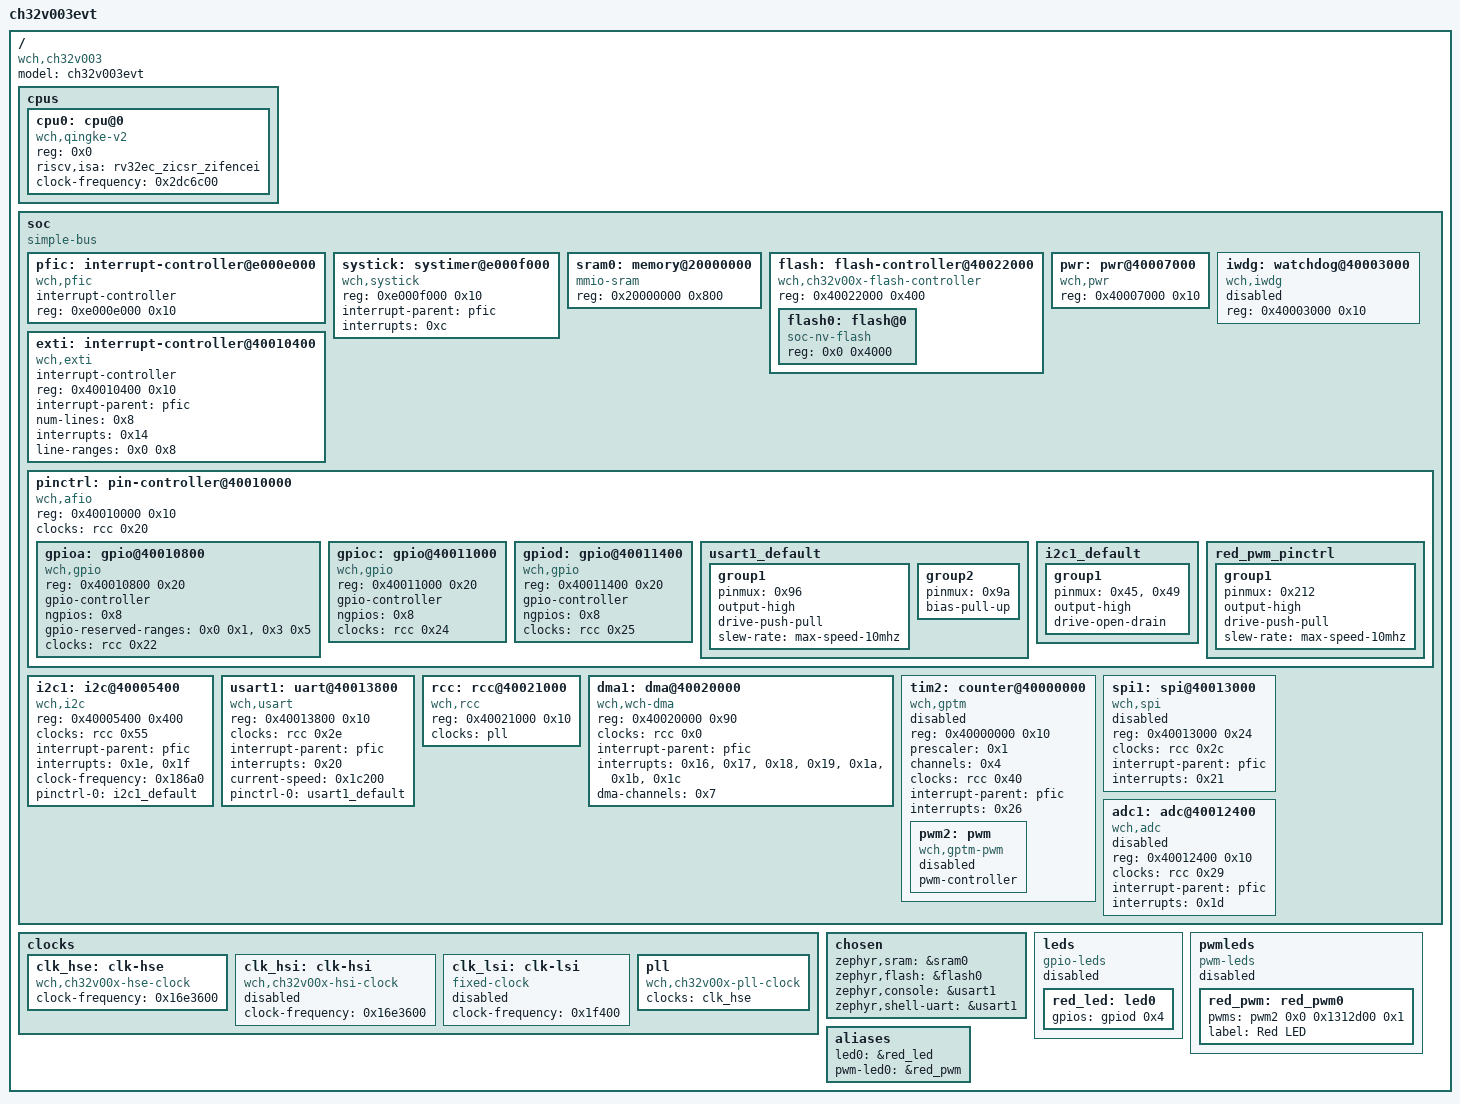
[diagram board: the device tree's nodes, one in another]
/dts-v1/;

/* node '/' defined in zephyr/dts/riscv/wch/qingke-v2a.dtsi:7 */
/ {
	#address-cells = < 0x1 >;    /* in zephyr/dts/riscv/wch/qingke-v2a.dtsi:8 */
	#size-cells = < 0x1 >;       /* in zephyr/dts/riscv/wch/qingke-v2a.dtsi:9 */
	model = "ch32v003evt";       /* in zephyr/boards/wch/ch32v003evt/ch32v003evt.dts:16 */
	compatible = "wch,ch32v003"; /* in zephyr/boards/wch/ch32v003evt/ch32v003evt.dts:17 */

	/* node '/cpus' defined in zephyr/dts/riscv/wch/qingke-v2a.dtsi:11 */
	cpus {
		#address-cells = < 0x1 >; /* in zephyr/dts/riscv/wch/qingke-v2a.dtsi:12 */
		#size-cells = < 0x0 >;    /* in zephyr/dts/riscv/wch/qingke-v2a.dtsi:13 */

		/* node '/cpus/cpu@0' defined in zephyr/dts/riscv/wch/qingke-v2a.dtsi:15 */
		cpu0: cpu@0 {
			device_type = "cpu";                 /* in zephyr/dts/riscv/wch/qingke-v2a.dtsi:16 */
			compatible = "wch,qingke-v2";        /* in zephyr/dts/riscv/wch/qingke-v2a.dtsi:17 */
			reg = < 0x0 >;                       /* in zephyr/dts/riscv/wch/qingke-v2a.dtsi:18 */
			riscv,isa = "rv32ec_zicsr_zifencei"; /* in zephyr/dts/riscv/wch/qingke-v2a.dtsi:19 */
			clock-frequency = < 0x2dc6c00 >;     /* in zephyr/dts/riscv/wch/ch32v0/ch32v003.dtsi:203 */
		};
	};

	/* node '/soc' defined in zephyr/dts/riscv/wch/qingke-v2a.dtsi:23 */
	soc {
		#address-cells = < 0x1 >;  /* in zephyr/dts/riscv/wch/qingke-v2a.dtsi:24 */
		#size-cells = < 0x1 >;     /* in zephyr/dts/riscv/wch/qingke-v2a.dtsi:25 */
		compatible = "simple-bus"; /* in zephyr/dts/riscv/wch/qingke-v2a.dtsi:26 */
		ranges;                    /* in zephyr/dts/riscv/wch/qingke-v2a.dtsi:27 */

		/* node '/soc/interrupt-controller@e000e000' defined in zephyr/dts/riscv/wch/qingke-v2a.dtsi:29 */
		pfic: interrupt-controller@e000e000 {
			compatible = "wch,pfic";    /* in zephyr/dts/riscv/wch/qingke-v2a.dtsi:30 */
			#address-cells = < 0x0 >;   /* in zephyr/dts/riscv/wch/qingke-v2a.dtsi:31 */
			#interrupt-cells = < 0x1 >; /* in zephyr/dts/riscv/wch/qingke-v2a.dtsi:32 */
			interrupt-controller;       /* in zephyr/dts/riscv/wch/qingke-v2a.dtsi:33 */
			reg = < 0xe000e000 0x10 >;  /* in zephyr/dts/riscv/wch/qingke-v2a.dtsi:34 */
			status = "okay";            /* in zephyr/dts/riscv/wch/qingke-v2a.dtsi:35 */
			phandle = < 0x1 >;          /* in zephyr/dts/riscv/wch/qingke-v2a.dtsi:42 */
		};

		/* node '/soc/systimer@e000f000' defined in zephyr/dts/riscv/wch/qingke-v2a.dtsi:38 */
		systick: systimer@e000f000 {
			compatible = "wch,systick";   /* in zephyr/dts/riscv/wch/qingke-v2a.dtsi:39 */
			reg = < 0xe000f000 0x10 >;    /* in zephyr/dts/riscv/wch/qingke-v2a.dtsi:40 */
			status = "okay";              /* in zephyr/dts/riscv/wch/qingke-v2a.dtsi:41 */
			interrupt-parent = < &pfic >; /* in zephyr/dts/riscv/wch/qingke-v2a.dtsi:42 */
			interrupts = < 0xc >;         /* in zephyr/dts/riscv/wch/qingke-v2a.dtsi:43 */
		};

		/* node '/soc/memory@20000000' defined in zephyr/dts/riscv/wch/ch32v0/ch32v003.dtsi:46 */
		sram0: memory@20000000 {
			compatible = "mmio-sram";   /* in zephyr/dts/riscv/wch/ch32v0/ch32v003.dtsi:47 */
			reg = < 0x20000000 0x800 >; /* in zephyr/dts/riscv/wch/ch32v0/ch32v003.dtsi:48 */
		};

		/* node '/soc/flash-controller@40022000' defined in zephyr/dts/riscv/wch/ch32v0/ch32v003.dtsi:51 */
		flash: flash-controller@40022000 {
			compatible = "wch,ch32v00x-flash-controller"; /* in zephyr/dts/riscv/wch/ch32v0/ch32v003.dtsi:52 */
			reg = < 0x40022000 0x400 >;                   /* in zephyr/dts/riscv/wch/ch32v0/ch32v003.dtsi:53 */
			#address-cells = < 0x1 >;                     /* in zephyr/dts/riscv/wch/ch32v0/ch32v003.dtsi:55 */
			#size-cells = < 0x1 >;                        /* in zephyr/dts/riscv/wch/ch32v0/ch32v003.dtsi:56 */

			/* node '/soc/flash-controller@40022000/flash@0' defined in zephyr/dts/riscv/wch/ch32v0/ch32v003.dtsi:58 */
			flash0: flash@0 {
				compatible = "soc-nv-flash"; /* in zephyr/dts/riscv/wch/ch32v0/ch32v003.dtsi:59 */
				reg = < 0x0 0x4000 >;        /* in zephyr/dts/riscv/wch/ch32v0/ch32v003.dtsi:60 */
			};
		};

		/* node '/soc/pwr@40007000' defined in zephyr/dts/riscv/wch/ch32v0/ch32v003.dtsi:64 */
		pwr: pwr@40007000 {
			compatible = "wch,pwr";    /* in zephyr/dts/riscv/wch/ch32v0/ch32v003.dtsi:65 */
			reg = < 0x40007000 0x10 >; /* in zephyr/dts/riscv/wch/ch32v0/ch32v003.dtsi:66 */
		};

		/* node '/soc/watchdog@40003000' defined in zephyr/dts/riscv/wch/ch32v0/ch32v003.dtsi:69 */
		iwdg: watchdog@40003000 {
			compatible = "wch,iwdg";   /* in zephyr/dts/riscv/wch/ch32v0/ch32v003.dtsi:70 */
			reg = < 0x40003000 0x10 >; /* in zephyr/dts/riscv/wch/ch32v0/ch32v003.dtsi:71 */
			status = "disabled";       /* in zephyr/dts/riscv/wch/ch32v0/ch32v003.dtsi:72 */
		};

		/* node '/soc/interrupt-controller@40010400' defined in zephyr/dts/riscv/wch/ch32v0/ch32v003.dtsi:75 */
		exti: interrupt-controller@40010400 {
			compatible = "wch,exti";      /* in zephyr/dts/riscv/wch/ch32v0/ch32v003.dtsi:76 */
			interrupt-controller;         /* in zephyr/dts/riscv/wch/ch32v0/ch32v003.dtsi:77 */
			#interrupt-cells = < 0x1 >;   /* in zephyr/dts/riscv/wch/ch32v0/ch32v003.dtsi:78 */
			reg = < 0x40010400 0x10 >;    /* in zephyr/dts/riscv/wch/ch32v0/ch32v003.dtsi:79 */
			interrupt-parent = < &pfic >; /* in zephyr/dts/riscv/wch/ch32v0/ch32v003.dtsi:80 */
			num-lines = < 0x8 >;          /* in zephyr/dts/riscv/wch/ch32v0/ch32v003.dtsi:81 */
			interrupts = < 0x14 >;        /* in zephyr/dts/riscv/wch/ch32v0/ch32v003.dtsi:82 */
			line-ranges = < 0x0 0x8 >;    /* in zephyr/dts/riscv/wch/ch32v0/ch32v003.dtsi:83 */
			interrupt-names = "line0-7";  /* in zephyr/dts/riscv/wch/ch32v0/ch32v003.dtsi:84 */
			status = "okay";              /* in zephyr/boards/wch/ch32v003evt/ch32v003evt.dts:72 */
		};

		/* node '/soc/pin-controller@40010000' defined in zephyr/dts/riscv/wch/ch32v0/ch32v003.dtsi:88 */
		pinctrl: pin-controller@40010000 {
			compatible = "wch,afio";   /* in zephyr/dts/riscv/wch/ch32v0/ch32v003.dtsi:89 */
			reg = < 0x40010000 0x10 >; /* in zephyr/dts/riscv/wch/ch32v0/ch32v003.dtsi:90 */
			#address-cells = < 0x1 >;  /* in zephyr/dts/riscv/wch/ch32v0/ch32v003.dtsi:91 */
			#size-cells = < 0x1 >;     /* in zephyr/dts/riscv/wch/ch32v0/ch32v003.dtsi:92 */
			clocks = < &rcc 0x20 >;    /* in zephyr/dts/riscv/wch/ch32v0/ch32v003.dtsi:93 */
			status = "okay";           /* in zephyr/dts/riscv/wch/ch32v0/ch32v003.dtsi:94 */

			/* node '/soc/pin-controller@40010000/gpio@40010800' defined in zephyr/dts/riscv/wch/ch32v0/ch32v003.dtsi:96 */
			gpioa: gpio@40010800 {
				compatible = "wch,gpio";            /* in zephyr/dts/riscv/wch/ch32v0/ch32v003.dtsi:97 */
				reg = < 0x40010800 0x20 >;          /* in zephyr/dts/riscv/wch/ch32v0/ch32v003.dtsi:98 */
				gpio-controller;                    /* in zephyr/dts/riscv/wch/ch32v0/ch32v003.dtsi:99 */
				#gpio-cells = < 0x2 >;              /* in zephyr/dts/riscv/wch/ch32v0/ch32v003.dtsi:100 */
				ngpios = < 0x8 >;                   /* in zephyr/dts/riscv/wch/ch32v0/ch32v003.dtsi:101 */
				gpio-reserved-ranges = < 0x0 0x1 >,
				                       < 0x3 0x5 >; /* in zephyr/dts/riscv/wch/ch32v0/ch32v003.dtsi:102 */
				clocks = < &rcc 0x22 >;             /* in zephyr/dts/riscv/wch/ch32v0/ch32v003.dtsi:103 */
			};

			/* node '/soc/pin-controller@40010000/gpio@40011000' defined in zephyr/dts/riscv/wch/ch32v0/ch32v003.dtsi:106 */
			gpioc: gpio@40011000 {
				compatible = "wch,gpio";   /* in zephyr/dts/riscv/wch/ch32v0/ch32v003.dtsi:107 */
				reg = < 0x40011000 0x20 >; /* in zephyr/dts/riscv/wch/ch32v0/ch32v003.dtsi:108 */
				gpio-controller;           /* in zephyr/dts/riscv/wch/ch32v0/ch32v003.dtsi:109 */
				#gpio-cells = < 0x2 >;     /* in zephyr/dts/riscv/wch/ch32v0/ch32v003.dtsi:110 */
				ngpios = < 0x8 >;          /* in zephyr/dts/riscv/wch/ch32v0/ch32v003.dtsi:111 */
				clocks = < &rcc 0x24 >;    /* in zephyr/dts/riscv/wch/ch32v0/ch32v003.dtsi:112 */
				status = "okay";           /* in zephyr/boards/wch/ch32v003evt/ch32v003evt.dts:76 */
			};

			/* node '/soc/pin-controller@40010000/gpio@40011400' defined in zephyr/dts/riscv/wch/ch32v0/ch32v003.dtsi:115 */
			gpiod: gpio@40011400 {
				compatible = "wch,gpio";   /* in zephyr/dts/riscv/wch/ch32v0/ch32v003.dtsi:116 */
				reg = < 0x40011400 0x20 >; /* in zephyr/dts/riscv/wch/ch32v0/ch32v003.dtsi:117 */
				gpio-controller;           /* in zephyr/dts/riscv/wch/ch32v0/ch32v003.dtsi:118 */
				#gpio-cells = < 0x2 >;     /* in zephyr/dts/riscv/wch/ch32v0/ch32v003.dtsi:119 */
				ngpios = < 0x8 >;          /* in zephyr/dts/riscv/wch/ch32v0/ch32v003.dtsi:120 */
				clocks = < &rcc 0x25 >;    /* in zephyr/dts/riscv/wch/ch32v0/ch32v003.dtsi:121 */
				status = "okay";           /* in zephyr/boards/wch/ch32v003evt/ch32v003evt.dts:80 */
				phandle = < 0x7 >;         /* in zephyr/boards/wch/ch32v003evt/ch32v003evt.dts:37 */
			};

			/* node '/soc/pin-controller@40010000/usart1_default' defined in zephyr/boards/wch/ch32v003evt/ch32v003evt-pinctrl.dtsi:9 */
			usart1_default: usart1_default {
				phandle = < 0x4 >; /* in zephyr/boards/wch/ch32v003evt/ch32v003evt.dts:93 */

				/* node '/soc/pin-controller@40010000/usart1_default/group1' defined in zephyr/boards/wch/ch32v003evt/ch32v003evt-pinctrl.dtsi:10 */
				group1 {
					pinmux = < 0x96 >;             /* in zephyr/boards/wch/ch32v003evt/ch32v003evt-pinctrl.dtsi:11 */
					output-high;                   /* in zephyr/boards/wch/ch32v003evt/ch32v003evt-pinctrl.dtsi:12 */
					drive-push-pull;               /* in zephyr/boards/wch/ch32v003evt/ch32v003evt-pinctrl.dtsi:13 */
					slew-rate = "max-speed-10mhz"; /* in zephyr/boards/wch/ch32v003evt/ch32v003evt-pinctrl.dtsi:14 */
				};

				/* node '/soc/pin-controller@40010000/usart1_default/group2' defined in zephyr/boards/wch/ch32v003evt/ch32v003evt-pinctrl.dtsi:17 */
				group2 {
					pinmux = < 0x9a >; /* in zephyr/boards/wch/ch32v003evt/ch32v003evt-pinctrl.dtsi:18 */
					bias-pull-up;      /* in zephyr/boards/wch/ch32v003evt/ch32v003evt-pinctrl.dtsi:19 */
				};
			};

			/* node '/soc/pin-controller@40010000/i2c1_default' defined in zephyr/boards/wch/ch32v003evt/ch32v003evt-pinctrl.dtsi:23 */
			i2c1_default: i2c1_default {
				phandle = < 0x3 >; /* in zephyr/boards/wch/ch32v003evt/ch32v003evt.dts:86 */

				/* node '/soc/pin-controller@40010000/i2c1_default/group1' defined in zephyr/boards/wch/ch32v003evt/ch32v003evt-pinctrl.dtsi:24 */
				group1 {
					pinmux = < 0x45 >,
					         < 0x49 >; /* in zephyr/boards/wch/ch32v003evt/ch32v003evt-pinctrl.dtsi:25 */
					output-high;       /* in zephyr/boards/wch/ch32v003evt/ch32v003evt-pinctrl.dtsi:26 */
					drive-open-drain;  /* in zephyr/boards/wch/ch32v003evt/ch32v003evt-pinctrl.dtsi:27 */
				};
			};

			/* node '/soc/pin-controller@40010000/red_pwm_pinctrl' defined in zephyr/boards/wch/ch32v003evt/ch32v003evt-pinctrl.dtsi:31 */
			red_pwm_pinctrl: red_pwm_pinctrl {

				/* node '/soc/pin-controller@40010000/red_pwm_pinctrl/group1' defined in zephyr/boards/wch/ch32v003evt/ch32v003evt-pinctrl.dtsi:32 */
				group1 {
					pinmux = < 0x212 >;            /* in zephyr/boards/wch/ch32v003evt/ch32v003evt-pinctrl.dtsi:33 */
					output-high;                   /* in zephyr/boards/wch/ch32v003evt/ch32v003evt-pinctrl.dtsi:34 */
					drive-push-pull;               /* in zephyr/boards/wch/ch32v003evt/ch32v003evt-pinctrl.dtsi:35 */
					slew-rate = "max-speed-10mhz"; /* in zephyr/boards/wch/ch32v003evt/ch32v003evt-pinctrl.dtsi:36 */
				};
			};
		};

		/* node '/soc/i2c@40005400' defined in zephyr/dts/riscv/wch/ch32v0/ch32v003.dtsi:125 */
		i2c1: i2c@40005400 {
			compatible = "wch,i2c";        /* in zephyr/dts/riscv/wch/ch32v0/ch32v003.dtsi:126 */
			#address-cells = < 0x1 >;      /* in zephyr/dts/riscv/wch/ch32v0/ch32v003.dtsi:127 */
			#size-cells = < 0x0 >;         /* in zephyr/dts/riscv/wch/ch32v0/ch32v003.dtsi:128 */
			reg = < 0x40005400 0x400 >;    /* in zephyr/dts/riscv/wch/ch32v0/ch32v003.dtsi:129 */
			clocks = < &rcc 0x55 >;        /* in zephyr/dts/riscv/wch/ch32v0/ch32v003.dtsi:130 */
			interrupt-parent = < &pfic >;  /* in zephyr/dts/riscv/wch/ch32v0/ch32v003.dtsi:131 */
			interrupts = < 0x1e >,
			             < 0x1f >;         /* in zephyr/dts/riscv/wch/ch32v0/ch32v003.dtsi:132 */
			status = "okay";               /* in zephyr/boards/wch/ch32v003evt/ch32v003evt.dts:84 */
			clock-frequency = < 0x186a0 >; /* in zephyr/boards/wch/ch32v003evt/ch32v003evt.dts:85 */
			pinctrl-0 = < &i2c1_default >; /* in zephyr/boards/wch/ch32v003evt/ch32v003evt.dts:86 */
			pinctrl-names = "default";     /* in zephyr/boards/wch/ch32v003evt/ch32v003evt.dts:87 */
		};

		/* node '/soc/uart@40013800' defined in zephyr/dts/riscv/wch/ch32v0/ch32v003.dtsi:135 */
		usart1: uart@40013800 {
			compatible = "wch,usart";        /* in zephyr/dts/riscv/wch/ch32v0/ch32v003.dtsi:136 */
			reg = < 0x40013800 0x10 >;       /* in zephyr/dts/riscv/wch/ch32v0/ch32v003.dtsi:137 */
			clocks = < &rcc 0x2e >;          /* in zephyr/dts/riscv/wch/ch32v0/ch32v003.dtsi:138 */
			interrupt-parent = < &pfic >;    /* in zephyr/dts/riscv/wch/ch32v0/ch32v003.dtsi:139 */
			interrupts = < 0x20 >;           /* in zephyr/dts/riscv/wch/ch32v0/ch32v003.dtsi:140 */
			status = "okay";                 /* in zephyr/boards/wch/ch32v003evt/ch32v003evt.dts:91 */
			current-speed = < 0x1c200 >;     /* in zephyr/boards/wch/ch32v003evt/ch32v003evt.dts:92 */
			pinctrl-0 = < &usart1_default >; /* in zephyr/boards/wch/ch32v003evt/ch32v003evt.dts:93 */
			pinctrl-names = "default";       /* in zephyr/boards/wch/ch32v003evt/ch32v003evt.dts:94 */
		};

		/* node '/soc/rcc@40021000' defined in zephyr/dts/riscv/wch/ch32v0/ch32v003.dtsi:143 */
		rcc: rcc@40021000 {
			compatible = "wch,rcc";    /* in zephyr/dts/riscv/wch/ch32v0/ch32v003.dtsi:144 */
			reg = < 0x40021000 0x10 >; /* in zephyr/dts/riscv/wch/ch32v0/ch32v003.dtsi:145 */
			#clock-cells = < 0x1 >;    /* in zephyr/dts/riscv/wch/ch32v0/ch32v003.dtsi:146 */
			status = "okay";           /* in zephyr/dts/riscv/wch/ch32v0/ch32v003.dtsi:147 */
			clocks = < &pll >;         /* in zephyr/boards/wch/ch32v003evt/ch32v003evt.dts:68 */
			phandle = < 0x2 >;         /* in zephyr/dts/riscv/wch/ch32v0/ch32v003.dtsi:93 */
		};

		/* node '/soc/dma@40020000' defined in zephyr/dts/riscv/wch/ch32v0/ch32v003.dtsi:150 */
		dma1: dma@40020000 {
			compatible = "wch,wch-dma";   /* in zephyr/dts/riscv/wch/ch32v0/ch32v003.dtsi:151 */
			reg = < 0x40020000 0x90 >;    /* in zephyr/dts/riscv/wch/ch32v0/ch32v003.dtsi:152 */
			clocks = < &rcc 0x0 >;        /* in zephyr/dts/riscv/wch/ch32v0/ch32v003.dtsi:153 */
			#dma-cells = < 0x1 >;         /* in zephyr/dts/riscv/wch/ch32v0/ch32v003.dtsi:154 */
			interrupt-parent = < &pfic >; /* in zephyr/dts/riscv/wch/ch32v0/ch32v003.dtsi:155 */
			interrupts = < 0x16 >,
			             < 0x17 >,
			             < 0x18 >,
			             < 0x19 >,
			             < 0x1a >,
			             < 0x1b >,
			             < 0x1c >;        /* in zephyr/dts/riscv/wch/ch32v0/ch32v003.dtsi:156 */
			dma-channels = < 0x7 >;       /* in zephyr/dts/riscv/wch/ch32v0/ch32v003.dtsi:157 */
		};

		/* node '/soc/counter@40000000' defined in zephyr/dts/riscv/wch/ch32v0/ch32v003.dtsi:160 */
		tim2: counter@40000000 {
			compatible = "wch,gptm";      /* in zephyr/dts/riscv/wch/ch32v0/ch32v003.dtsi:161 */
			reg = < 0x40000000 0x10 >;    /* in zephyr/dts/riscv/wch/ch32v0/ch32v003.dtsi:162 */
			prescaler = < 0x1 >;          /* in zephyr/dts/riscv/wch/ch32v0/ch32v003.dtsi:163 */
			channels = < 0x4 >;           /* in zephyr/dts/riscv/wch/ch32v0/ch32v003.dtsi:164 */
			clocks = < &rcc 0x40 >;       /* in zephyr/dts/riscv/wch/ch32v0/ch32v003.dtsi:165 */
			interrupt-parent = < &pfic >; /* in zephyr/dts/riscv/wch/ch32v0/ch32v003.dtsi:166 */
			interrupts = < 0x26 >;        /* in zephyr/dts/riscv/wch/ch32v0/ch32v003.dtsi:167 */
			interrupt-names = "global";   /* in zephyr/dts/riscv/wch/ch32v0/ch32v003.dtsi:168 */
			status = "disabled";          /* in zephyr/dts/riscv/wch/ch32v0/ch32v003.dtsi:169 */

			/* node '/soc/counter@40000000/pwm' defined in zephyr/dts/riscv/wch/ch32v0/ch32v003.dtsi:171 */
			pwm2: pwm {
				compatible = "wch,gptm-pwm"; /* in zephyr/dts/riscv/wch/ch32v0/ch32v003.dtsi:172 */
				pwm-controller;              /* in zephyr/dts/riscv/wch/ch32v0/ch32v003.dtsi:173 */
				#pwm-cells = < 0x3 >;        /* in zephyr/dts/riscv/wch/ch32v0/ch32v003.dtsi:174 */
				status = "disabled";         /* in zephyr/dts/riscv/wch/ch32v0/ch32v003.dtsi:175 */
				phandle = < 0x8 >;           /* in zephyr/boards/wch/ch32v003evt/ch32v003evt.dts:46 */
			};
		};

		/* node '/soc/spi@40013000' defined in zephyr/dts/riscv/wch/ch32v0/ch32v003.dtsi:179 */
		spi1: spi@40013000 {
			compatible = "wch,spi";       /* in zephyr/dts/riscv/wch/ch32v0/ch32v003.dtsi:180 */
			reg = < 0x40013000 0x24 >;    /* in zephyr/dts/riscv/wch/ch32v0/ch32v003.dtsi:181 */
			clocks = < &rcc 0x2c >;       /* in zephyr/dts/riscv/wch/ch32v0/ch32v003.dtsi:182 */
			interrupt-parent = < &pfic >; /* in zephyr/dts/riscv/wch/ch32v0/ch32v003.dtsi:183 */
			interrupts = < 0x21 >;        /* in zephyr/dts/riscv/wch/ch32v0/ch32v003.dtsi:184 */
			status = "disabled";          /* in zephyr/dts/riscv/wch/ch32v0/ch32v003.dtsi:185 */
			#address-cells = < 0x1 >;     /* in zephyr/dts/riscv/wch/ch32v0/ch32v003.dtsi:186 */
			#size-cells = < 0x0 >;        /* in zephyr/dts/riscv/wch/ch32v0/ch32v003.dtsi:187 */
		};

		/* node '/soc/adc@40012400' defined in zephyr/dts/riscv/wch/ch32v0/ch32v003.dtsi:190 */
		adc1: adc@40012400 {
			compatible = "wch,adc";       /* in zephyr/dts/riscv/wch/ch32v0/ch32v003.dtsi:191 */
			reg = < 0x40012400 0x10 >;    /* in zephyr/dts/riscv/wch/ch32v0/ch32v003.dtsi:192 */
			clocks = < &rcc 0x29 >;       /* in zephyr/dts/riscv/wch/ch32v0/ch32v003.dtsi:193 */
			interrupt-parent = < &pfic >; /* in zephyr/dts/riscv/wch/ch32v0/ch32v003.dtsi:194 */
			interrupts = < 0x1d >;        /* in zephyr/dts/riscv/wch/ch32v0/ch32v003.dtsi:195 */
			#io-channel-cells = < 0x1 >;  /* in zephyr/dts/riscv/wch/ch32v0/ch32v003.dtsi:196 */
			status = "disabled";          /* in zephyr/dts/riscv/wch/ch32v0/ch32v003.dtsi:197 */
		};
	};

	/* node '/clocks' defined in zephyr/dts/riscv/wch/ch32v0/ch32v003.dtsi:17 */
	clocks {

		/* node '/clocks/clk-hse' defined in zephyr/dts/riscv/wch/ch32v0/ch32v003.dtsi:18 */
		clk_hse: clk-hse {
			#clock-cells = < 0x0 >;                /* in zephyr/dts/riscv/wch/ch32v0/ch32v003.dtsi:19 */
			compatible = "wch,ch32v00x-hse-clock"; /* in zephyr/dts/riscv/wch/ch32v0/ch32v003.dtsi:20 */
			clock-frequency = < 0x16e3600 >;       /* in zephyr/boards/wch/ch32v003evt/ch32v003evt.dts:58 */
			status = "okay";                       /* in zephyr/boards/wch/ch32v003evt/ch32v003evt.dts:59 */
			phandle = < 0x6 >;                     /* in zephyr/boards/wch/ch32v003evt/ch32v003evt.dts:63 */
		};

		/* node '/clocks/clk-hsi' defined in zephyr/dts/riscv/wch/ch32v0/ch32v003.dtsi:24 */
		clk_hsi: clk-hsi {
			#clock-cells = < 0x0 >;                /* in zephyr/dts/riscv/wch/ch32v0/ch32v003.dtsi:25 */
			compatible = "wch,ch32v00x-hsi-clock"; /* in zephyr/dts/riscv/wch/ch32v0/ch32v003.dtsi:26 */
			clock-frequency = < 0x16e3600 >;       /* in zephyr/dts/riscv/wch/ch32v0/ch32v003.dtsi:27 */
			status = "disabled";                   /* in zephyr/dts/riscv/wch/ch32v0/ch32v003.dtsi:28 */
		};

		/* node '/clocks/clk-lsi' defined in zephyr/dts/riscv/wch/ch32v0/ch32v003.dtsi:31 */
		clk_lsi: clk-lsi {
			#clock-cells = < 0x0 >;        /* in zephyr/dts/riscv/wch/ch32v0/ch32v003.dtsi:32 */
			compatible = "fixed-clock";    /* in zephyr/dts/riscv/wch/ch32v0/ch32v003.dtsi:33 */
			clock-frequency = < 0x1f400 >; /* in zephyr/dts/riscv/wch/ch32v0/ch32v003.dtsi:34 */
			status = "disabled";           /* in zephyr/dts/riscv/wch/ch32v0/ch32v003.dtsi:35 */
		};

		/* node '/clocks/pll' defined in zephyr/dts/riscv/wch/ch32v0/ch32v003.dtsi:38 */
		pll: pll {
			#clock-cells = < 0x0 >;                /* in zephyr/dts/riscv/wch/ch32v0/ch32v003.dtsi:39 */
			compatible = "wch,ch32v00x-pll-clock"; /* in zephyr/dts/riscv/wch/ch32v0/ch32v003.dtsi:40 */
			clocks = < &clk_hse >;                 /* in zephyr/boards/wch/ch32v003evt/ch32v003evt.dts:63 */
			status = "okay";                       /* in zephyr/boards/wch/ch32v003evt/ch32v003evt.dts:64 */
			phandle = < 0x5 >;                     /* in zephyr/boards/wch/ch32v003evt/ch32v003evt.dts:68 */
		};
	};

	/* node '/chosen' defined in zephyr/boards/wch/ch32v003evt/ch32v003evt.dts:19 */
	chosen {
		zephyr,sram = &sram0;        /* in zephyr/boards/wch/ch32v003evt/ch32v003evt.dts:20 */
		zephyr,flash = &flash0;      /* in zephyr/boards/wch/ch32v003evt/ch32v003evt.dts:21 */
		zephyr,console = &usart1;    /* in zephyr/boards/wch/ch32v003evt/ch32v003evt.dts:22 */
		zephyr,shell-uart = &usart1; /* in zephyr/boards/wch/ch32v003evt/ch32v003evt.dts:23 */
	};

	/* node '/leds' defined in zephyr/boards/wch/ch32v003evt/ch32v003evt.dts:26 */
	leds {
		compatible = "gpio-leds"; /* in zephyr/boards/wch/ch32v003evt/ch32v003evt.dts:27 */
		status = "disabled";      /* in zephyr/boards/wch/ch32v003evt/ch32v003evt.dts:34 */

		/* node '/leds/led0' defined in zephyr/boards/wch/ch32v003evt/ch32v003evt.dts:36 */
		red_led: led0 {
			gpios = < &gpiod 0x4 0x0 >; /* in zephyr/boards/wch/ch32v003evt/ch32v003evt.dts:37 */
		};
	};

	/* node '/pwmleds' defined in zephyr/boards/wch/ch32v003evt/ch32v003evt.dts:41 */
	pwmleds: pwmleds {
		compatible = "pwm-leds"; /* in zephyr/boards/wch/ch32v003evt/ch32v003evt.dts:42 */
		status = "disabled";     /* in zephyr/boards/wch/ch32v003evt/ch32v003evt.dts:43 */

		/* node '/pwmleds/red_pwm0' defined in zephyr/boards/wch/ch32v003evt/ch32v003evt.dts:45 */
		red_pwm: red_pwm0 {
			pwms = < &pwm2 0x0 0x1312d00 0x1 >; /* in zephyr/boards/wch/ch32v003evt/ch32v003evt.dts:46 */
			label = "Red LED";                  /* in zephyr/boards/wch/ch32v003evt/ch32v003evt.dts:47 */
		};
	};

	/* node '/aliases' defined in zephyr/boards/wch/ch32v003evt/ch32v003evt.dts:51 */
	aliases {
		led0 = &red_led;     /* in zephyr/boards/wch/ch32v003evt/ch32v003evt.dts:52 */
		pwm-led0 = &red_pwm; /* in zephyr/boards/wch/ch32v003evt/ch32v003evt.dts:53 */
	};
};
